# ADSP-2183xW_LPC register map
Vendor: Analog Devices; Series: ADSP-2183xW_LPC; File version: 3.0.3.517
CPU: 
Registers are 32-bit, read-write, reset 0x0 unless marked. A register's access mark holds for its fields unless they carry their own. Offsets are from the block's base; [hi:lo] are bit positions; {n}, {i} and the like mark numbered series; 'fields as' and 'values as' point back to an identical list.

## PADS0 — Pads Controller
Base 0x31004600
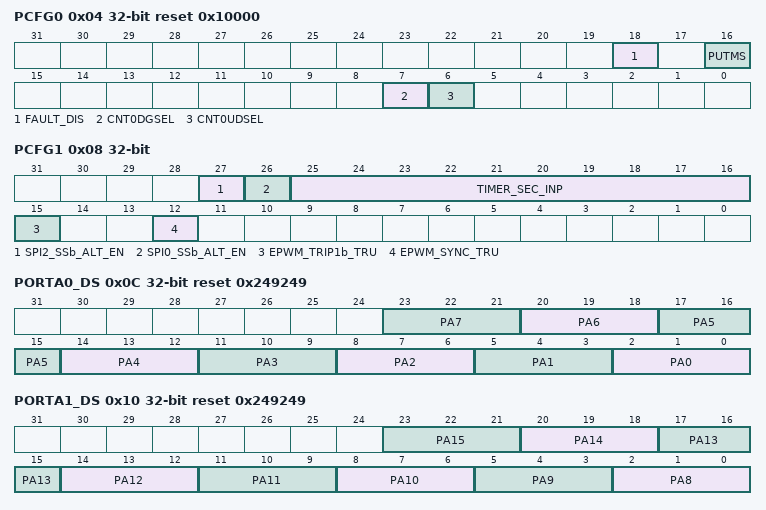
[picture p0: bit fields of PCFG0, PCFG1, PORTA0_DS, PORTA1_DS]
0x04 PCFG0 reset 0x10000 — Peripheral PAD Configuration0 Register
  [18] FAULT_DIS — FAULT does not exist
  [16] PUTMS — Pull-Up Enable for TMS/SWDIO (debug port)
  [7] CNT0DGSEL — CNT0 Down Input Select
  [6] CNT0UDSEL — CNT0 Up Input Select
0x08 PCFG1 — Peripheral Configuration1 Register
  [27] SPI2_SSb_ALT_EN range 0x00000000..0x00000001 — Alternate Pin input enable for SPI2_SSb. 0: PA[5]. 1: PE[2]
  [26] SPI0_SSb_ALT_EN range 0x00000000..0x00000001 — Alternate Pin input enable for SPI0_SSb. 0: PA[9]. 1: PE[15]
  [25:16] TIMER_SEC_INP — Secondary Input Select
    1=TIMER0_CLK; 2=TIMER0_ACI0; 4=TIMER0_ACI1; 8=TIMER0_ACI2; 16=TIMER0_ACI3; 32=TIMER0_ACI4; 64=TIMER0_ACLK1
  [15] EPWM_TRIP1b_TRU range 0x00000000..0x00000001 — PWM TRIP1b input enable
  [12] EPWM_SYNC_TRU range 0x00000000..0x00000001 — PWM SYNC Enable
0x0C PORTA0_DS reset 0x249249 — PORTA 0 to 7 pins DS control
  [3n+2:3n] PA{n} (n=0..7) — DS control for PA{n} IO
0x10 PORTA1_DS reset 0x249249 — PORTA 8 - 15 pins DS control
  [3n-22:3n-24] PA{n} (n=8..15) — DS control for PA{n} IO
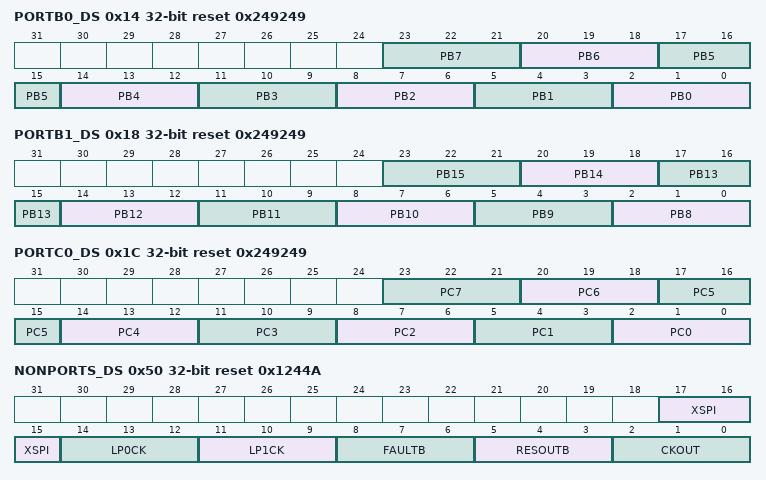
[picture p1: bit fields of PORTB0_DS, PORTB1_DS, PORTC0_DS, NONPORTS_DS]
0x14 PORTB0_DS reset 0x249249 — PORTB 0 to 7 pins DS control
  [3n+2:3n] PB{n} (n=0..7) — DS control for PB{n} IO
0x18 PORTB1_DS reset 0x249249 — PORTB 8 - 15 pins DS control
  [3n-22:3n-24] PB{n} (n=8..15) — DS control for PB{n} IO
0x1C PORTC0_DS reset 0x249249 — PORTC 0 to 7 pins DS control
  [3n+2:3n] PC{n} (n=0..7) — DS control for PC{n} IO
0x50 NONPORTS_DS reset 0x1244A — Non-GPIO Drive Strength Register
  [17:15] XSPI — XSPI pins DS control
  [14:12] LP0CK — LP0 Clock Drive Strength Control
  [11:9] LP1CK — LP1 Clock Drive Strength Control
  [8:6] FAULTB — FAULTB DS control
  [5:3] RESOUTB — RESOUTB DS control
  [2:0] CKOUT — CLKOUT DS control
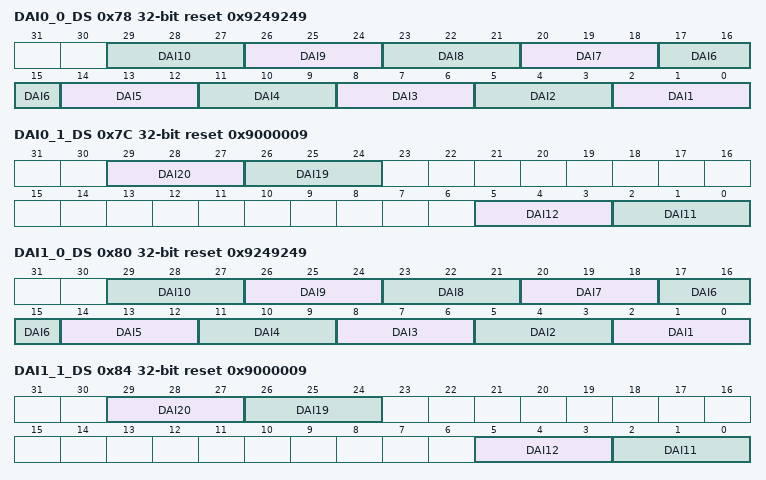
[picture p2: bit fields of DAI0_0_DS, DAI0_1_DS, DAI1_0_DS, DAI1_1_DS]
0x78 DAI0_0_DS reset 0x9249249 — DAI0 1 to 10 pins DS control
  [3n-1:3n-3] DAI{n} (n=1..10) — DS control for DAI{n} IO
0x7C DAI0_1_DS reset 0x9000009 — DAI0 11 to 20 pins DS control
  [29:27] DAI20 — DS control for DAI20 IO
  [26:24] DAI19 — DS control for DAI19 IO
  [5:3] DAI12 — DS control for DAI12 IO
  [2:0] DAI11 — DS control for DAI11 IO
0x80 DAI1_0_DS reset 0x9249249 — DAI1 1 to 10 pins DS control
  [3n-1:3n-3] DAI{n} (n=1..10) — DS control for DAI{n} IO
0x84 DAI1_1_DS reset 0x9000009 — DAI1 11 to 20 pins DS control
  fields as DAI0_1_DS
0x90 DAI0_IE — DAI0 Port Input Enable Control Register
  [19:0] VALUE range 0x00000000..0x000FFFFF — DAI0 Input Enable Control
0x94 DAI1_IE — DAI1 Port Input Enable Control Register
  [19:0] VALUE range 0x00000000..0x000FFFFF — DAI1 Input Enable Control
0x98 PORTA_PUE — PORT[n] Pull-Up Enable
  [15:0] PUE range 0x00000000..0x0000FFFF — Pull-Up Enable
0x9C PORTB_PUE — PORT[n] Pull-Up Enable
  [15:0] PUE range 0x00000000..0x0000FFFF — Pull-Up Enable
0xA0 PORTC_PUE — PORT[n] Pull-Up Enable
  [15:0] PUE range 0x00000000..0x0000FFFF — Pull-Up Enable
0xBC DAI0_PUE — DAI[n] Pull-Up Enable
  [19:0] PUE range 0x00000000..0x000FFFFF — Pull-Up Enable
0xC0 DAI1_PUE — DAI[n] Pull-Up Enable
  [19:0] PUE range 0x00000000..0x000FFFFF — Pull-Up Enable
0xC4 PORTA_PDE — PORT[n] Pull-Down Enable
  [15:0] PDE range 0x00000000..0x0000FFFF — Pull-Down Enable
0xC8 PORTB_PDE — PORT[n] Pull-Down Enable
  [15:0] PDE range 0x00000000..0x0000FFFF — Pull-Down Enable
0xCC PORTC_PDE — PORT[n] Pull-Down Enable
  [15:0] PDE range 0x00000000..0x0000FFFF — Pull-Down Enable
0xFC DAI0_PDE — DAI[n] Pull-Down Enable
  [19:0] PDE range 0x00000000..0x000FFFFF — Pull-Down Enable
0x100 DAI1_PDE — DAI[n] Pull-Down Enable
  [19:0] PDE range 0x00000000..0x000FFFFF — Pull-Down Enable

## PINT0 — The Pin Interrupt module
Base 0x31005000
Same registers: PINT1 0x31005100, PINT2 0x31005200
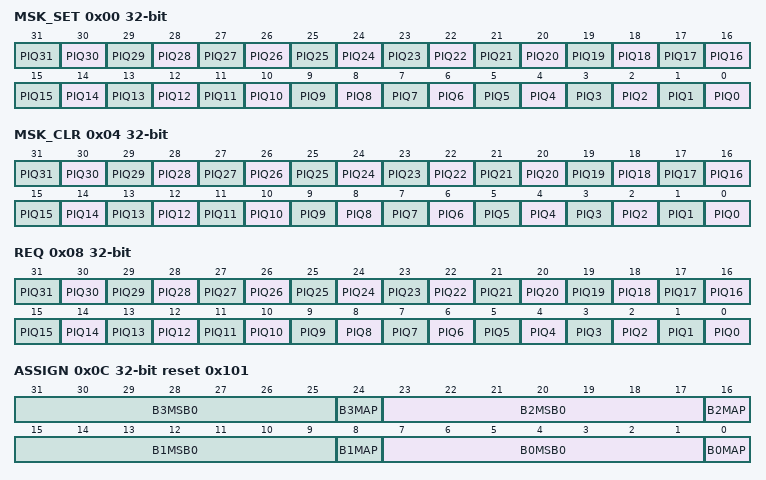
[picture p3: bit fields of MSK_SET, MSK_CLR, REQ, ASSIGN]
0x00 MSK_SET — PINT Mask Set Register
  [n] PIQ{n} range 0x00000000..0x00000001 (n=0..31) — Pin Interrupt {n} Unmask
0x04 MSK_CLR — PINT Mask Clear Register
  [n] PIQ{n} range 0x00000000..0x00000001 (n=0..31) — Pin Interrupt {n} Mask
0x08 REQ — PINT Request Register
  [n] PIQ{n} range 0x00000000..0x00000001 (n=0..31) — Pin Interrupt {n} Request
0x0C ASSIGN reset 0x101 — PINT Assign Register
  [8n+7:8n+1] B{n}MSB0 ro (n=0..3) — Bits [7:1] of B{n}MAP
  [8n] B{n}MAP (n=0..3) — Byte {n} Mapping
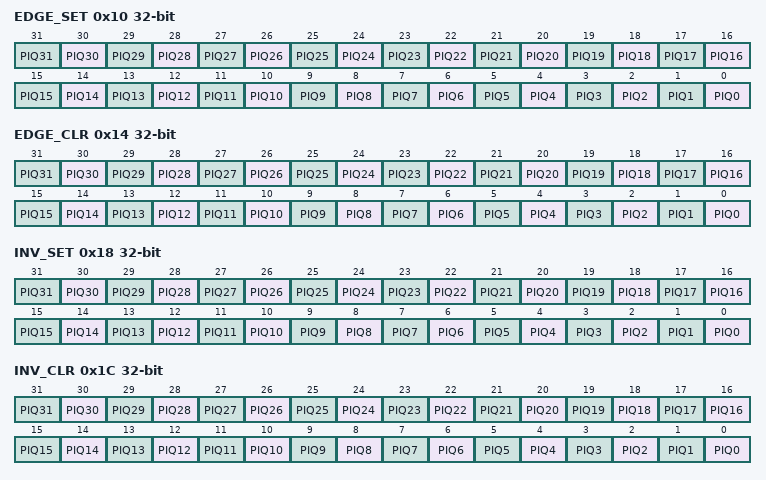
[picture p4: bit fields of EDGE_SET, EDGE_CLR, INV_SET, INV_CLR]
0x10 EDGE_SET — PINT Edge Set Register
  [n] PIQ{n} range 0x00000000..0x00000001 (n=0..31) — Pin Interrupt {n} Edge
0x14 EDGE_CLR — PINT Edge Clear Register
  [n] PIQ{n} range 0x00000000..0x00000001 (n=0..31) — Pin Interrupt {n} Level
0x18 INV_SET — PINT Invert Set Register
  [n] PIQ{n} range 0x00000000..0x00000001 (n=0..31) — Pin Interrupt {n} Invert
0x1C INV_CLR — PINT Invert Clear Register
  [n] PIQ{n} range 0x00000000..0x00000001 (n=0..31) — Pin Interrupt {n} No Invert
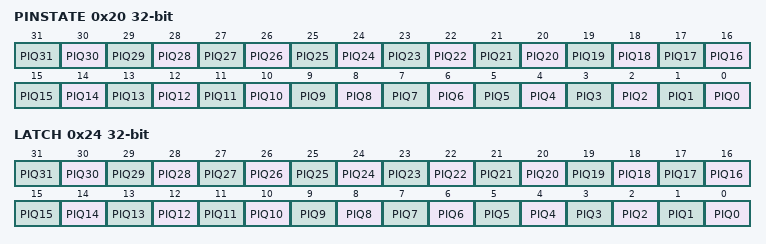
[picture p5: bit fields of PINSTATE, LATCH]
0x20 PINSTATE — PINT Pin State Register
  [n] PIQ{n} ro (n=0..31) — Pin Interrupt {n} State
0x24 LATCH — PINT Latch Register
  [n] PIQ{n} range 0x00000000..0x00000001 (n=0..31) — Pin Interrupt {n} Latch
